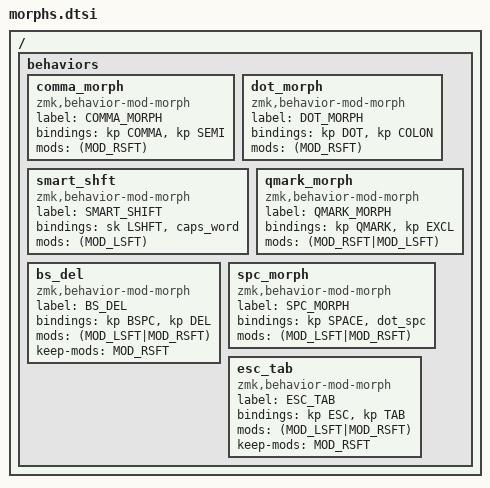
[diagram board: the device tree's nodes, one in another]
/ {
  behaviors {
    comma_morph: comma_morph {
      compatible = "zmk,behavior-mod-morph";
      label = "COMMA_MORPH";
      #binding-cells = <0>;
      bindings = <&kp COMMA>, <&kp SEMI>;
      mods = <(MOD_RSFT)>;
    };
    dot_morph: dot_morph {
      compatible = "zmk,behavior-mod-morph";
      label = "DOT_MORPH";
      #binding-cells = <0>;
      bindings = <&kp DOT>, <&kp COLON>;
      mods = <(MOD_RSFT)>;
    };
    smart_shft: smart_shft {
      compatible = "zmk,behavior-mod-morph";
      label = "SMART_SHIFT";
      #binding-cells = <0>;
      bindings = <&sk LSHFT>, <&caps_word>;
      mods = <(MOD_LSFT)>;
    };
    qmark_morph: qmark_morph {
      compatible = "zmk,behavior-mod-morph";
      label = "QMARK_MORPH";
      #binding-cells = <0>;
      bindings = <&kp QMARK>, <&kp EXCL>;
      mods = <(MOD_RSFT|MOD_LSFT)>;
    };
    bs_del: bs_del {
      compatible = "zmk,behavior-mod-morph";
      label = "BS_DEL";
      #binding-cells = <0>;
      bindings = <&kp BSPC>, <&kp DEL>;
      mods = <(MOD_LSFT|MOD_RSFT)>;
      keep-mods = <MOD_RSFT>;
    };
    spc_morph: spc_morph {
      compatible = "zmk,behavior-mod-morph";
      label = "SPC_MORPH";
      #binding-cells = <0>;
      bindings  = <&kp SPACE>, <&dot_spc>;
      mods = <(MOD_LSFT|MOD_RSFT)>;
     };
    esc_tab: esc_tab {
      compatible = "zmk,behavior-mod-morph";
      label = "ESC_TAB";
      #binding-cells = <0>;
      bindings = <&kp ESC>, <&kp TAB>;
      mods = <(MOD_LSFT|MOD_RSFT)>;
      keep-mods = <MOD_RSFT>;
    };
  };
};
